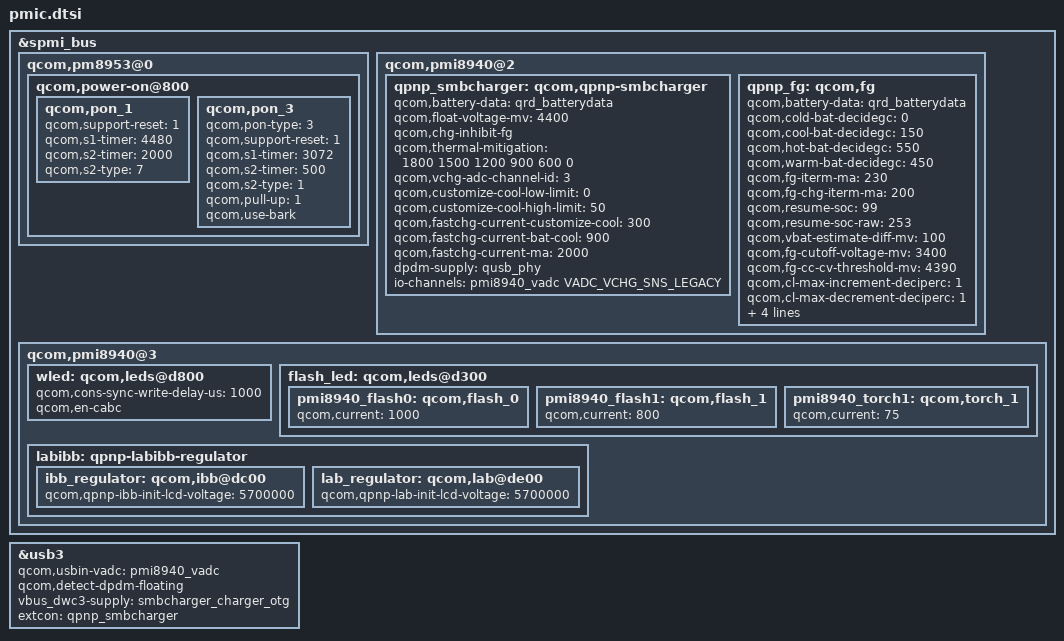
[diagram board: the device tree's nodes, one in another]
&spmi_bus {
	qcom,pm8953@0 {
		qcom,power-on@800 {
			qcom,pon_1 {
				qcom,support-reset = <1>;
				qcom,s1-timer = <4480>;
				qcom,s2-timer = <2000>;
				qcom,s2-type = <7>;
			};

			qcom,pon_3 {
				qcom,pon-type = <3>;
				qcom,support-reset = <1>;
				qcom,s1-timer = <3072>;
				qcom,s2-timer = <500>;
				qcom,s2-type = <1>;
				qcom,pull-up = <1>;
				qcom,use-bark;
			};
		};

		/delete-node/ qcom,pm8953_typec@bf00;
	};	
};

&spmi_bus {
	qcom,pmi8940@2 {
		qpnp_smbcharger: qcom,qpnp-smbcharger {
			qcom,battery-data = <&qrd_batterydata>;
			qcom,float-voltage-mv = <4400>;
			qcom,chg-inhibit-fg;
			qcom,thermal-mitigation = <1800 1500 1200 900 600 0>;
			status = "okay";
			qcom,vchg-adc-channel-id = <3>;
			qcom,customize-cool-low-limit = <0>;
			qcom,customize-cool-high-limit = <50>;
			qcom,fastchg-current-customize-cool = <300>;
			qcom,fastchg-current-bat-cool = <900>;
			qcom,fastchg-current-ma = <2000>;
			dpdm-supply = <&qusb_phy>;
			io-channels = <&pmi8940_vadc VADC_VCHG_SNS_LEGACY>;
			io-channel-names = "vchg_sns";
		};

		qpnp_fg: qcom,fg {
			qcom,battery-data = <&qrd_batterydata>;
			qcom,cold-bat-decidegc = <0>;
			qcom,cool-bat-decidegc = <150>;
			qcom,hot-bat-decidegc = <550>;
			qcom,warm-bat-decidegc = <450>;
			qcom,fg-iterm-ma = <230>;
			qcom,fg-chg-iterm-ma = <200>;
			qcom,resume-soc = <99>;
			qcom,resume-soc-raw = <253>;
			qcom,vbat-estimate-diff-mv = <100>;
			qcom,fg-cutoff-voltage-mv = <3400>;
			qcom,fg-cc-cv-threshold-mv = <4390>;
			qcom,cl-max-increment-deciperc = <1>;
			qcom,cl-max-decrement-deciperc = <1>;
			qcom,fg-delta-soc = <2>;
			qcom,bad-battery-detection-enable;
			qcom,hold-soc-while-full;
			qcom,thermal-coefficients = [DA 86 F0 50 08 3C];
		};
	};

	qcom,pmi8940@3 {
		wled: qcom,leds@d800 {
			qcom,cons-sync-write-delay-us = <1000>;
			qcom,en-cabc;
		};

		flash_led: qcom,leds@d300 {
			pmi8940_flash0: qcom,flash_0 {
				qcom,current = <1000>;
			};

			pmi8940_flash1: qcom,flash_1 {
				qcom,current = <800>;
			};

			pmi8940_torch1: qcom,torch_1 {
				qcom,current = <75>;
			};
		};  
	};
};

&usb3 {
	qcom,usbin-vadc = <&pmi8940_vadc>;
	qcom,detect-dpdm-floating;
	vbus_dwc3-supply = <&smbcharger_charger_otg>;
	extcon = <&qpnp_smbcharger>;
};

&spmi_bus {
	qcom,pmi8940@3 {
		labibb: qpnp-labibb-regulator {
			ibb_regulator: qcom,ibb@dc00 {
				/delete-property/
					qcom,qpnp-ibb-use-default-voltage;
				qcom,qpnp-ibb-init-lcd-voltage = <5700000>;
			};

			lab_regulator: qcom,lab@de00 {
				/delete-property/
					qcom,qpnp-lab-use-default-voltage;
				qcom,qpnp-lab-init-lcd-voltage = <5700000>;
			};
		};
	};
};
